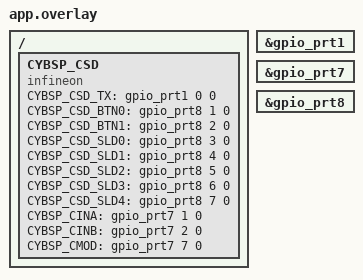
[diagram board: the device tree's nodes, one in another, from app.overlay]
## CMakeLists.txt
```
# SPDX-License-Identifier: Apache-2.0

cmake_minimum_required(VERSION 3.20.0)

find_package(Zephyr REQUIRED HINTS $ENV{ZEPHYR_BASE})
project(capsense_buttons_slider)

set(PDL_DRIVER_DIR ${ZEPHYR_HAL_INFINEON_MODULE_DIR}/mtb-pdl-cat1/drivers/source)
set(HAL_SOURCE_DIR ${ZEPHYR_HAL_INFINEON_MODULE_DIR}/mtb-hal-cat1/COMPONENT_PSOC6HAL/source)
set(CAPSENSE_LIB_DIR "${ZEPHYR_HAL_INFINEON_MODULE_DIR}/../../lib/capsense")

zephyr_library_sources(${PDL_DRIVER_DIR}/cy_tcpwm_pwm.c ${PDL_DRIVER_DIR}/cy_scb_ezi2c.c ${PDL_DRIVER_DIR}/cy_scb_i2c.c)
zephyr_library_sources(${HAL_SOURCE_DIR}/cyhal_pwm.c ${HAL_SOURCE_DIR}/cyhal_tcpwm_common.c ${HAL_SOURCE_DIR}/cyhal_ezi2c.c)
zephyr_include_directories(${CAPSENSE_LIB_DIR})
FILE(GLOB capsense_sources ${CAPSENSE_LIB_DIR}/*.c)
zephyr_library_sources(${capsense_sources} ${PDL_DRIVER_DIR}/cy_csd.c)

add_definitions( -DCOMPONENT_CUSTOM_DESIGN_MODUS )

zephyr_include_directories(GeneratedSource src)
FILE(GLOB app_sources GeneratedSource/*c src/*.c)
target_sources(app PRIVATE ${app_sources})

add_library(libcy_capsense STATIC IMPORTED GLOBAL)
set_target_properties(libcy_capsense PROPERTIES IMPORTED_LOCATION ${CAPSENSE_LIB_DIR}/COMPONENT_SOFTFP/TOOLCHAIN_GCC_ARM/libcy_capsense.a)
target_link_libraries(app PUBLIC libcy_capsense)
```

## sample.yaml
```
sample:
  name: CAPSENSE Buttons and Slider
tests:
  sample.basic.capsense:
    tags: gpio
    filter: dt_enabled_alias_with_parent_compat("gpio-led")
    depends_on: gpio
    harness: gpio
```

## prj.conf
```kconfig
CONFIG_NEWLIB_LIBC=y
CONFIG_BOOT_BANNER=n
```

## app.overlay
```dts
/*
 * Copyright (c) 2021 Nordic Semiconductor ASA
 *
 * SPDX-License-Identifier: Apache-2.0
 */

/ {
	/* CAPSENSE configuration */
	CYBSP_CSD {
	status = "okay";
	compatible = "infineon";

	/* CAPSENSE pins */
	CYBSP_CSD_TX   = <&gpio_prt1 0 0>;
	CYBSP_CSD_BTN0 = <&gpio_prt8 1 0>;
	CYBSP_CSD_BTN1 = <&gpio_prt8 2 0>;
	CYBSP_CSD_SLD0 = <&gpio_prt8 3 0>;
	CYBSP_CSD_SLD1 = <&gpio_prt8 4 0>;
	CYBSP_CSD_SLD2 = <&gpio_prt8 5 0>;
	CYBSP_CSD_SLD3 = <&gpio_prt8 6 0>;
	CYBSP_CSD_SLD4 = <&gpio_prt8 7 0>;
	CYBSP_CINA     = <&gpio_prt7 1 0>;
	CYBSP_CINB     = <&gpio_prt7 2 0>;
	CYBSP_CMOD     = <&gpio_prt7 7 0>;
	};
};

&gpio_prt1 {
	status = "okay";
};

&gpio_prt7 {
	status = "okay";
};

&gpio_prt8 {
	status = "okay";
};
```

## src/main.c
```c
/******************************************************************************
* File Name: main.c
*
* Description: This code example features a 5-segment CAPSENSE slider and two
*              CAPSENSE buttons. Button 0 turns the LED ON, Button 1 turns the
*              LED OFF, and the slider controls the brightness of the LED. The
*              code example also features interfacing with Tuner GUI using I2C
*              interface.
*
*              This code example uses Zephyr. For documentation and API
*              references of Zephyr, visit : https://docs.zephyrproject.org
*
* Related Document: See README.md
*
*
*******************************************************************************
* Copyright 2019-2023, Cypress Semiconductor Corporation (an Infineon company) or
* an affiliate of Cypress Semiconductor Corporation.  All rights reserved.
*
* This software, including source code, documentation and related
* materials ("Software") is owned by Cypress Semiconductor Corporation
* or one of its affiliates ("Cypress") and is protected by and subject to
* worldwide patent protection (United States and foreign),
* United States copyright laws and international treaty provisions.
* Therefore, you may use this Software only as provided in the license
* agreement accompanying the software package from which you
* obtained this Software ("EULA").
* If no EULA applies, Cypress hereby grants you a personal, non-exclusive,
* non-transferable license to copy, modify, and compile the Software
* source code solely for use in connection with Cypress's
* integrated circuit products.  Any reproduction, modification, translation,
* compilation, or representation of this Software except as specified
* above is prohibited without the express written permission of Cypress.
*
* Disclaimer: THIS SOFTWARE IS PROVIDED AS-IS, WITH NO WARRANTY OF ANY KIND,
* EXPRESS OR IMPLIED, INCLUDING, BUT NOT LIMITED TO, NONINFRINGEMENT, IMPLIED
* WARRANTIES OF MERCHANTABILITY AND FITNESS FOR A PARTICULAR PURPOSE. Cypress
* reserves the right to make changes to the Software without notice. Cypress
* does not assume any liability arising out of the application or use of the
* Software or any product or circuit described in the Software. Cypress does
* not authorize its products for use in any products where a malfunction or
* failure of the Cypress product may reasonably be expected to result in
* significant property damage, injury or death ("High Risk Product"). By
* including Cypress's product in a High Risk Product, the manufacturer
* of such system or application assumes all risk of such use and in doing
* so agrees to indemnify Cypress against all liability.
*******************************************************************************/

#include "cybsp.h"
#include "capsense_task.h"
#include "led_task.h"
#include <zephyr/device.h>


/*******************************************************************************
 * Global constants
 ******************************************************************************/
/* Priorities of user tasks in this project. */
#define TASK_CAPSENSE_PRIORITY   (6u)
#define TASK_LED_PRIORITY        (5u)

/* Stack sizes of user tasks in this project */
#define TASK_CAPSENSE_STACK_SIZE (1024u)
#define TASK_LED_STACK_SIZE      (512u)


/*******************************************************************************
 * Global variable
 ******************************************************************************/
/* Create the threads. See the respective task definition for more
    * details of these tasks.
    */
K_THREAD_DEFINE(task_capsense_id, TASK_CAPSENSE_STACK_SIZE, task_capsense,
            NULL, NULL, NULL, TASK_CAPSENSE_PRIORITY, 0, -1);
K_THREAD_DEFINE(task_led_id, TASK_LED_STACK_SIZE, task_led,
            NULL, NULL, NULL, TASK_LED_PRIORITY, 0, -1);


/*******************************************************************************
* Function Name: main()
********************************************************************************
* Summary:
*  System entrance point. This function sets up user tasks and then starts
*  the RTOS scheduler.
*
* Return:
*  int
*
*******************************************************************************/
void main(void)
{
    cy_rslt_t result;

    /* Initialize the device and board peripherals */
    result = cybsp_init();

    /* Board init failed. Stop program execution */
    if (result != CY_RSLT_SUCCESS)
    {
        CY_ASSERT(0);
    }

    /* Enable global interrupts */
    __enable_irq();

    /* Started the created threads */
    k_thread_start(task_capsense_id);
    k_thread_start(task_led_id);
}


/* [] END OF FILE */
```

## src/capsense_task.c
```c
/*******************************************************************************
* File Name: capsense_task.c
*
* Description: This file contains the task that handles touch sensing.
*
* Related Document: README.md
*
*******************************************************************************
* Copyright 2019-2023, Cypress Semiconductor Corporation (an Infineon company) or
* an affiliate of Cypress Semiconductor Corporation.  All rights reserved.
*
* This software, including source code, documentation and related
* materials ("Software") is owned by Cypress Semiconductor Corporation
* or one of its affiliates ("Cypress") and is protected by and subject to
* worldwide patent protection (United States and foreign),
* United States copyright laws and international treaty provisions.
* Therefore, you may use this Software only as provided in the license
* agreement accompanying the software package from which you
* obtained this Software ("EULA").
* If no EULA applies, Cypress hereby grants you a personal, non-exclusive,
* non-transferable license to copy, modify, and compile the Software
* source code solely for use in connection with Cypress's
* integrated circuit products.  Any reproduction, modification, translation,
* compilation, or representation of this Software except as specified
* above is prohibited without the express written permission of Cypress.
*
* Disclaimer: THIS SOFTWARE IS PROVIDED AS-IS, WITH NO WARRANTY OF ANY KIND,
* EXPRESS OR IMPLIED, INCLUDING, BUT NOT LIMITED TO, NONINFRINGEMENT, IMPLIED
* WARRANTIES OF MERCHANTABILITY AND FITNESS FOR A PARTICULAR PURPOSE. Cypress
* reserves the right to make changes to the Software without notice. Cypress
* does not assume any liability arising out of the application or use of the
* Software or any product or circuit described in the Software. Cypress does
* not authorize its products for use in any products where a malfunction or
* failure of the Cypress product may reasonably be expected to result in
* significant property damage, injury or death ("High Risk Product"). By
* including Cypress's product in a High Risk Product, the manufacturer
* of such system or application assumes all risk of such use and in doing
* so agrees to indemnify Cypress against all liability.
*******************************************************************************/


/******************************************************************************
* Header files includes
******************************************************************************/
#include "cybsp.h"
#include "cycfg.h"
#include "cyhal.h"
#include "cycfg_capsense.h"
#include "capsense_task.h"
#include "led_task.h"


/*******************************************************************************
* Global constants
*******************************************************************************/
#define CAPSENSE_INTERRUPT_PRIORITY    (7u)
#define EZI2C_INTERRUPT_PRIORITY    (6u)    /* EZI2C interrupt priority must be
                                             * higher than CAPSENSE interrupt
                                             */
#define CAPSENSE_SCAN_INTERVAL_MS    (20u)   /* in milliseconds*/


/*******************************************************************************
* Function Prototypes
*******************************************************************************/
static uint32_t capsense_init(void);
static void tuner_init(void);
static void process_touch(void);
static void capsense_isr(void);
static void capsense_end_of_scan_callback(cy_stc_active_scan_sns_t* active_scan_sns_ptr);
static void capsense_timer_callback(struct k_timer *params);
void handle_error(void);


/******************************************************************************
* Global variables
******************************************************************************/
cy_stc_scb_ezi2c_context_t ezi2c_context;
cyhal_ezi2c_t sEzI2C;
cyhal_ezi2c_slave_cfg_t sEzI2C_sub_cfg;
cyhal_ezi2c_cfg_t sEzI2C_cfg;

/* Queue handle used for LED data */
K_FIFO_DEFINE(capsense_command_q);
/* Initialize timer for periodic CAPSENSE scan */
K_TIMER_DEFINE(scan_timer_handle, capsense_timer_callback, NULL);

/* SysPm callback params */
cy_stc_syspm_callback_params_t callback_params =
{
    .base       = CYBSP_CSD_HW,
    .context    = &cy_capsense_context
};

cy_stc_syspm_callback_t capsense_deep_sleep_cb =
{
    Cy_CapSense_DeepSleepCallback,
    CY_SYSPM_DEEPSLEEP,
    (CY_SYSPM_SKIP_CHECK_FAIL | CY_SYSPM_SKIP_BEFORE_TRANSITION | CY_SYSPM_SKIP_AFTER_TRANSITION),
    &callback_params,
    NULL,
    NULL
};


/*******************************************************************************
* Function Name: handle_error
********************************************************************************
* Summary:
* User defined error handling function
*
* Parameters:
*  void
*
* Return:
*  void
*
*******************************************************************************/
void handle_error(void)
{
    /* Disable all interrupts. */
    __disable_irq();

    CY_ASSERT(0);
}


/*******************************************************************************
* Function Name: task_capsense
********************************************************************************
* Summary:
*  Task that initializes the CAPSENSE block and processes the touch input.
*
* Parameters:
*  void *param : Task parameter defined during task creation (unused)
*
*******************************************************************************/
void task_capsense(void *dummy1, void *dummy2, void *dummy3)
{
    cy_status status;
    capsense_command_t *capsense_cmd;

    /* Remove warning for unused parameter */
    ARG_UNUSED(dummy1);
	ARG_UNUSED(dummy2);
	ARG_UNUSED(dummy3);

    /* Setup communication between Tuner GUI and PSoC 6 MCU */
    tuner_init();

    /* Initialize CAPSENSE block */
    status = capsense_init();
    if(CY_RET_SUCCESS != status)
    {
        CY_ASSERT(0u);
    }

    /* Start the timer */
    k_timer_start(&scan_timer_handle, K_NO_WAIT,
                    K_MSEC(CAPSENSE_SCAN_INTERVAL_MS));

    /* Repeatedly running part of the task */
    for(;;)
    {
        /* Block until a CAPSENSE command has been received over queue */
        capsense_cmd = k_fifo_get(&capsense_command_q, K_FOREVER);

        /* Command has been received from capsense_cmd */
        /* Check if CAPSENSE is busy with a previous scan */
        if(CY_CAPSENSE_NOT_BUSY == Cy_CapSense_IsBusy(&cy_capsense_context))
        {
            switch(*capsense_cmd)
            {
                case CAPSENSE_SCAN:
                {
                    /* Start scan */
                    Cy_CapSense_ScanAllWidgets(&cy_capsense_context);
                    break;
                }
                case CAPSENSE_PROCESS:
                {
                    /* Process all widgets */
                    Cy_CapSense_ProcessAllWidgets(&cy_capsense_context);
                    process_touch();

                    /* Establishes synchronized operation between the CAPSENSE
                        * middleware and the CAPSENSE Tuner tool.
                        */
                    Cy_CapSense_RunTuner(&cy_capsense_context);
                    break;
                }
                /* Invalid command */
                default:
                {
                    break;
                }
            }
        }
    }
}


/*******************************************************************************
* Function Name: process_touch
********************************************************************************
* Summary:
*  This function processes the touch input and sends command to LED task.
*
*******************************************************************************/
static void process_touch(void)
{
    /* Variables used to store touch information */
    uint32_t button0_status = 0;
    uint32_t button1_status = 0;
    uint16_t slider_pos = 0;
    uint8_t slider_touched = 0;
    cy_stc_capsense_touch_t *slider_touch;

    /* Variables used to store previous touch information */
    static uint32_t button0_status_prev = 0;
    static uint32_t button1_status_prev = 0;
    static uint16_t slider_pos_perv = 0;

    /* Variables used for storing command and data for LED Task */
    led_command_data_t led_cmd_data;
    bool send_led_command = false;

    /* Get button 0 status */
    button0_status = Cy_CapSense_IsSensorActive(
        CY_CAPSENSE_BUTTON0_WDGT_ID,
        CY_CAPSENSE_BUTTON0_SNS0_ID,
        &cy_capsense_context);

    /* Get button 1 status */
    button1_status = Cy_CapSense_IsSensorActive(
        CY_CAPSENSE_BUTTON1_WDGT_ID,
        CY_CAPSENSE_BUTTON1_SNS0_ID,
        &cy_capsense_context);

    /* Get slider status */
    slider_touch = Cy_CapSense_GetTouchInfo(
        CY_CAPSENSE_LINEARSLIDER0_WDGT_ID,
        &cy_capsense_context);
    slider_pos = slider_touch->ptrPosition->x;
    slider_touched = slider_touch->numPosition;

    /* Detect new touch on Button0 */
    if((0u != button0_status) && (0u == button0_status_prev))
    {
        led_cmd_data.command = LED_TURN_ON;
        send_led_command = true;
    }

    /* Detect new touch on Button1 */
    if((0u != button1_status) && (0u == button1_status_prev))
    {
        led_cmd_data.command = LED_TURN_OFF;
        send_led_command = true;
    }

    /* Detect new touch on slider */
    if((0u != slider_touched) && (slider_pos_perv != slider_pos ))
    {
        led_cmd_data.command = LED_UPDATE_BRIGHTNESS;

        /* brightness in percentage */
        led_cmd_data.brightness = (slider_pos * 100)
                    / cy_capsense_context.ptrWdConfig[CY_CAPSENSE_LINEARSLIDER0_WDGT_ID].xResolution;
        send_led_command = true;
    }

    /* Send command to update LED state if required */
    if(send_led_command)
    {
        k_fifo_put(&led_command_data_q, &led_cmd_data);
    }

    /* Update previous touch status */
    button0_status_prev = button0_status;
    button1_status_prev = button1_status;
    slider_pos_perv = slider_pos;
}


/*******************************************************************************
* Function Name: capsense_init
********************************************************************************
* Summary:
*  This function initializes the CSD HW block, and configures the CAPSENSE
*  interrupt.
*
*******************************************************************************/
static uint32_t capsense_init(void)
{
    uint32_t status = CYRET_SUCCESS;

    /* CAPSENSE interrupt configuration parameters */
    static const cy_stc_sysint_t capSense_intr_config =
    {
        .intrSrc = csd_interrupt_IRQn,
        .intrPriority = CAPSENSE_INTERRUPT_PRIORITY,
    };

    /*Initialize CAPSENSE Data structures */
    status = Cy_CapSense_Init(&cy_capsense_context);
    if (CYRET_SUCCESS != status)
    {
        return status;
    }

    /* Initialize CAPSENSE interrupt */
    cyhal_system_set_isr(csd_interrupt_IRQn, csd_interrupt_IRQn, CAPSENSE_INTERRUPT_PRIORITY, &capsense_isr);
    NVIC_ClearPendingIRQ(capSense_intr_config.intrSrc);
    NVIC_EnableIRQ(capSense_intr_config.intrSrc);

    /* Initialize the CAPSENSE deep sleep callback functions. */
    Cy_CapSense_Enable(&cy_capsense_context);
    if (CYRET_SUCCESS != status)
    {
        return status;
    }
    Cy_SysPm_RegisterCallback(&capsense_deep_sleep_cb);
    /* Register end of scan callback */
    status = Cy_CapSense_RegisterCallback(CY_CAPSENSE_END_OF_SCAN_E,
                                              capsense_end_of_scan_callback, &cy_capsense_context);
    if (CYRET_SUCCESS != status)
    {
        return status;
    }

    return status;
}


/*******************************************************************************
* Function Name: capsense_end_of_scan_callback
********************************************************************************
* Summary:
*  CAPSENSE end of scan callback function. This function sends a command to
*  CAPSENSE task to process scan.
*
* Parameters:
*  cy_stc_active_scan_sns_t * active_scan_sns_ptr (unused)
*
*******************************************************************************/
static void capsense_end_of_scan_callback(cy_stc_active_scan_sns_t* active_scan_sns_ptr)
{
    ARG_UNUSED(active_scan_sns_ptr);

    /* Send command to process CAPSENSE data */
    static capsense_command_t command = CAPSENSE_PROCESS;
    k_fifo_put(&capsense_command_q, &command);
}


/*******************************************************************************
* Function Name: capsense_timer_callback
********************************************************************************
* Summary:
*  CAPSENSE timer callback. This function sends a command to start CAPSENSE
*  scan.
*
* Parameters:
*  struct k_timer dummy (unused)
*
*******************************************************************************/
static void capsense_timer_callback(struct k_timer *dummy)
{
    Cy_CapSense_Wakeup(&cy_capsense_context);
    static capsense_command_t command = CAPSENSE_SCAN;

    ARG_UNUSED(dummy);

    /* Send command to start CAPSENSE scan */
    k_fifo_put(&capsense_command_q, &command);
}


/*******************************************************************************
* Function Name: capsense_isr
********************************************************************************
* Summary:
*  Wrapper function for handling interrupts from CSD block.
*
*******************************************************************************/
static void capsense_isr(void)
{
    Cy_CapSense_InterruptHandler(CYBSP_CSD_HW, &cy_capsense_context);
}


/*******************************************************************************
* Function Name: tuner_init
********************************************************************************
* Summary:
*  Initializes communication between Tuner GUI and PSoC 6 MCU.
*
*******************************************************************************/
static void tuner_init(void)
{
    cy_rslt_t result;
    /* Configure CAPSENSE Tuner as EzI2C Slave */
    sEzI2C_sub_cfg.buf = (uint8_t *)&cy_capsense_tuner;
    sEzI2C_sub_cfg.buf_rw_boundary = sizeof(cy_capsense_tuner);
    sEzI2C_sub_cfg.buf_size = sizeof(cy_capsense_tuner);
    sEzI2C_sub_cfg.slave_address = 8U;

    sEzI2C_cfg.data_rate = CYHAL_EZI2C_DATA_RATE_400KHZ;
    sEzI2C_cfg.enable_wake_from_sleep = true;
    sEzI2C_cfg.slave1_cfg = sEzI2C_sub_cfg;
    sEzI2C_cfg.sub_address_size = CYHAL_EZI2C_SUB_ADDR16_BITS;
    sEzI2C_cfg.two_addresses = false;
    result = cyhal_ezi2c_init( &sEzI2C, CYBSP_I2C_SDA, CYBSP_I2C_SCL, NULL, &sEzI2C_cfg);
    if (result != CY_RSLT_SUCCESS)
    {
        handle_error();
    }

}


/* END OF FILE [] */
```

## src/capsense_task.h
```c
/******************************************************************************
* File Name: capsense_task.h
*
* Description: This file is the public interface of capsense_task.c source
*              file.
*
* Related Document: README.md
*
*******************************************************************************
* Copyright 2019-2023, Cypress Semiconductor Corporation (an Infineon company) or
* an affiliate of Cypress Semiconductor Corporation.  All rights reserved.
*
* This software, including source code, documentation and related
* materials ("Software") is owned by Cypress Semiconductor Corporation
* or one of its affiliates ("Cypress") and is protected by and subject to
* worldwide patent protection (United States and foreign),
* United States copyright laws and international treaty provisions.
* Therefore, you may use this Software only as provided in the license
* agreement accompanying the software package from which you
* obtained this Software ("EULA").
* If no EULA applies, Cypress hereby grants you a personal, non-exclusive,
* non-transferable license to copy, modify, and compile the Software
* source code solely for use in connection with Cypress's
* integrated circuit products.  Any reproduction, modification, translation,
* compilation, or representation of this Software except as specified
* above is prohibited without the express written permission of Cypress.
*
* Disclaimer: THIS SOFTWARE IS PROVIDED AS-IS, WITH NO WARRANTY OF ANY KIND,
* EXPRESS OR IMPLIED, INCLUDING, BUT NOT LIMITED TO, NONINFRINGEMENT, IMPLIED
* WARRANTIES OF MERCHANTABILITY AND FITNESS FOR A PARTICULAR PURPOSE. Cypress
* reserves the right to make changes to the Software without notice. Cypress
* does not assume any liability arising out of the application or use of the
* Software or any product or circuit described in the Software. Cypress does
* not authorize its products for use in any products where a malfunction or
* failure of the Cypress product may reasonably be expected to result in
* significant property damage, injury or death ("High Risk Product"). By
* including Cypress's product in a High Risk Product, the manufacturer
* of such system or application assumes all risk of such use and in doing
* so agrees to indemnify Cypress against all liability.
*******************************************************************************/


/*******************************************************************************
 *  Include guard
 ******************************************************************************/
#ifndef SOURCE_CAPSENSE_TASK_H_
#define SOURCE_CAPSENSE_TASK_H_


/*******************************************************************************
 * Header file includes
 ******************************************************************************/
#include <zephyr/kernel.h>


/*******************************************************************************
 * Enumeration
 ******************************************************************************/
typedef enum
{
    CAPSENSE_SCAN,
    CAPSENSE_PROCESS
} capsense_command_t;


/*******************************************************************************
 * Global variable
 ******************************************************************************/


/*******************************************************************************
 * Function prototype
 ******************************************************************************/
void task_capsense(void *dummy1, void *dummy2, void *dummy3);


#endif /* SOURCE_CAPSENSE_TASK_H_ */


/* END OF FILE [] */
```

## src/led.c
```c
/******************************************************************************
* File Name: led.c
*
* Description: This file contains source code that controls LED.
*
* Related Document: README.md
*
*******************************************************************************
* Copyright 2019-2023, Cypress Semiconductor Corporation (an Infineon company) or
* an affiliate of Cypress Semiconductor Corporation.  All rights reserved.
*
* This software, including source code, documentation and related
* materials ("Software") is owned by Cypress Semiconductor Corporation
* or one of its affiliates ("Cypress") and is protected by and subject to
* worldwide patent protection (United States and foreign),
* United States copyright laws and international treaty provisions.
* Therefore, you may use this Software only as provided in the license
* agreement accompanying the software package from which you
* obtained this Software ("EULA").
* If no EULA applies, Cypress hereby grants you a personal, non-exclusive,
* non-transferable license to copy, modify, and compile the Software
* source code solely for use in connection with Cypress's
* integrated circuit products.  Any reproduction, modification, translation,
* compilation, or representation of this Software except as specified
* above is prohibited without the express written permission of Cypress.
*
* Disclaimer: THIS SOFTWARE IS PROVIDED AS-IS, WITH NO WARRANTY OF ANY KIND,
* EXPRESS OR IMPLIED, INCLUDING, BUT NOT LIMITED TO, NONINFRINGEMENT, IMPLIED
* WARRANTIES OF MERCHANTABILITY AND FITNESS FOR A PARTICULAR PURPOSE. Cypress
* reserves the right to make changes to the Software without notice. Cypress
* does not assume any liability arising out of the application or use of the
* Software or any product or circuit described in the Software. Cypress does
* not authorize its products for use in any products where a malfunction or
* failure of the Cypress product may reasonably be expected to result in
* significant property damage, injury or death ("High Risk Product"). By
* including Cypress's product in a High Risk Product, the manufacturer
* of such system or application assumes all risk of such use and in doing
* so agrees to indemnify Cypress against all liability.
*******************************************************************************/

/*******************************************************************************
* Header files includes
*******************************************************************************/
#include "cybsp.h"
#include "cyhal.h"
#include "cycfg.h"
#include "led.h"

/*******************************************************************************
* Global constants
*******************************************************************************/
#define PWM_LED_FREQ_HZ    (1000000lu)  /* in Hz */
#define GET_DUTY_CYCLE(x)    (100 - x)

/*******************************************************************************
* Global constants
*******************************************************************************/
led_state_t led_state_cur = LED_OFF;
cyhal_pwm_t pwm_led;

/*******************************************************************************
* Function Name: update_led_state
********************************************************************************
* Summary:
*  This function updates the LED state, based on the touch input.
*
* Parameter:
*  ledData: the pointer to the LED data structure
*
*******************************************************************************/
void update_led_state(led_data_t *ledData)
{
    if ((led_state_cur == LED_OFF) && (ledData->state == LED_ON))
    {
        cyhal_pwm_start(&pwm_led);
        led_state_cur = LED_ON;
        ledData->brightness = LED_MAX_BRIGHTNESS;
    }
    else if ((led_state_cur == LED_ON) && (ledData->state == LED_OFF))
    {
        cyhal_pwm_stop(&pwm_led);
        led_state_cur = LED_OFF;
        ledData->brightness = 0;
    }
    else
    {
    }

    if ((LED_ON == led_state_cur) || ((LED_OFF == led_state_cur) && (ledData->brightness > 0)))
    {
        cyhal_pwm_start(&pwm_led);
        uint32_t brightness = (ledData->brightness < LED_MIN_BRIGHTNESS) ? LED_MIN_BRIGHTNESS : ledData->brightness;

        /* Drive the LED with brightness */
        cyhal_pwm_set_duty_cycle(&pwm_led, GET_DUTY_CYCLE(brightness),
                                 PWM_LED_FREQ_HZ);
        led_state_cur = LED_ON;
    }
}

/*******************************************************************************
* Function Name: initialize_led
********************************************************************************
* Summary:
*  Initializes a PWM resource for driving an LED.
*
*******************************************************************************/
cy_rslt_t initialize_led(void)
{
    cy_rslt_t rslt;

    rslt = cyhal_pwm_init(&pwm_led, CYBSP_USER_LED, NULL);

    if (CY_RSLT_SUCCESS == rslt)
    {
        rslt = cyhal_pwm_set_duty_cycle(&pwm_led,
                                        GET_DUTY_CYCLE(LED_MAX_BRIGHTNESS),
                                        PWM_LED_FREQ_HZ);
        if (CY_RSLT_SUCCESS == rslt)
        {
            rslt = cyhal_pwm_start(&pwm_led);
        }

    }

    if (CY_RSLT_SUCCESS == rslt)
    {
        led_state_cur = LED_ON;
    }

    return rslt;
}

/* [] END OF FILE */
```

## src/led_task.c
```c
/******************************************************************************
* File Name: led_task.c
*
* Description: This file contains the task that handles led.
*
* Related Document: README.md
*
*******************************************************************************
* Copyright 2019-2023, Cypress Semiconductor Corporation (an Infineon company) or
* an affiliate of Cypress Semiconductor Corporation.  All rights reserved.
*
* This software, including source code, documentation and related
* materials ("Software") is owned by Cypress Semiconductor Corporation
* or one of its affiliates ("Cypress") and is protected by and subject to
* worldwide patent protection (United States and foreign),
* United States copyright laws and international treaty provisions.
* Therefore, you may use this Software only as provided in the license
* agreement accompanying the software package from which you
* obtained this Software ("EULA").
* If no EULA applies, Cypress hereby grants you a personal, non-exclusive,
* non-transferable license to copy, modify, and compile the Software
* source code solely for use in connection with Cypress's
* integrated circuit products.  Any reproduction, modification, translation,
* compilation, or representation of this Software except as specified
* above is prohibited without the express written permission of Cypress.
*
* Disclaimer: THIS SOFTWARE IS PROVIDED AS-IS, WITH NO WARRANTY OF ANY KIND,
* EXPRESS OR IMPLIED, INCLUDING, BUT NOT LIMITED TO, NONINFRINGEMENT, IMPLIED
* WARRANTIES OF MERCHANTABILITY AND FITNESS FOR A PARTICULAR PURPOSE. Cypress
* reserves the right to make changes to the Software without notice. Cypress
* does not assume any liability arising out of the application or use of the
* Software or any product or circuit described in the Software. Cypress does
* not authorize its products for use in any products where a malfunction or
* failure of the Cypress product may reasonably be expected to result in
* significant property damage, injury or death ("High Risk Product"). By
* including Cypress's product in a High Risk Product, the manufacturer
* of such system or application assumes all risk of such use and in doing
* so agrees to indemnify Cypress against all liability.
*******************************************************************************/


/*******************************************************************************
 * Header file includes
 ******************************************************************************/
#include "cybsp.h"
#include "cycfg.h"
#include "cyhal.h"
#include "led_task.h"


/*******************************************************************************
* Global constants
*******************************************************************************/
#define PWM_LED_FREQ_HZ     (1000000u)  /* in Hz */
#define GET_DUTY_CYCLE(x)   (100 - x)   /* subtracting from 100 since the LED
                                         * is connected in active low
                                         * configuration
                                         */


/*******************************************************************************
 * Global variable
 ******************************************************************************/
/* Queue handle used for LED data */
K_FIFO_DEFINE(led_command_data_q);


/*******************************************************************************
* Function Name: task_led
********************************************************************************
* Summary:
*  Task that controls the LED.
*
* Parameters:
*  void *param : Task parameter defined during task creation (unused)
*
*******************************************************************************/
void task_led(void *dummy1, void *dummy2, void *dummy3)
{
    cyhal_pwm_t pwm_led;
    bool led_on = true;
    led_command_data_t *led_cmd_data;

    /* Suppress warning for unused parameter */
    ARG_UNUSED(dummy1);
	ARG_UNUSED(dummy2);
	ARG_UNUSED(dummy3);

    /* Initialize a PWM resource for driving an LED. */
    cyhal_pwm_init(&pwm_led, CYBSP_USER_LED, NULL);
    cyhal_pwm_set_duty_cycle(&pwm_led, GET_DUTY_CYCLE(LED_MAX_BRIGHTNESS),
                             PWM_LED_FREQ_HZ);
    cyhal_pwm_start(&pwm_led);

    /* Repeatedly running part of the task */
    for(;;)
    {
        /* Block until a command has been received over queue */
        led_cmd_data = k_fifo_get(&led_command_data_q, K_FOREVER);

        /* Command has been received from queue */
        switch(led_cmd_data->command)
        {
            /* Turn on the LED. */
            case LED_TURN_ON:
            {
                if (!led_on)
                {
                    /* Start PWM to turn the LED on */
                    cyhal_pwm_start(&pwm_led);
                    led_on = true;
                    led_cmd_data->brightness=LED_MAX_BRIGHTNESS;
                }
                break;
            }
            /* Turn off LED */
            case LED_TURN_OFF:
            {
                if(led_on)
                {
                    /* Stop PWM to turn the LED off */
                    cyhal_pwm_stop(&pwm_led);
                    led_on = false;
                    led_cmd_data->brightness=0;
                }
                break;
            }
            /* Update LED brightness */
            case LED_UPDATE_BRIGHTNESS:
            {
                if ((led_on) || ((!led_on) && (led_cmd_data->brightness>0)))
                {
                    /* Start PWM to turn the LED on */
                    cyhal_pwm_start(&pwm_led);
                    uint32_t brightness = (led_cmd_data->brightness < LED_MIN_BRIGHTNESS) ?
                                            LED_MIN_BRIGHTNESS : led_cmd_data->brightness;

                    /* Drive the LED with brightness */
                    cyhal_pwm_set_duty_cycle(&pwm_led, GET_DUTY_CYCLE(brightness),
                                                PWM_LED_FREQ_HZ);
                    led_on = true;
                }
                break;
            }
            /* Invalid command */
            default:
            {
                /* Handle invalid command here */
                break;
            }
        }
    }
}


/* END OF FILE [] */
```

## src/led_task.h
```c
/******************************************************************************
* File Name: led_task.h
*
* Description: This file is the public interface of led_task.c source file
*
* Related Document: README.md
*
*******************************************************************************
* Copyright 2019-2023, Cypress Semiconductor Corporation (an Infineon company) or
* an affiliate of Cypress Semiconductor Corporation.  All rights reserved.
*
* This software, including source code, documentation and related
* materials ("Software") is owned by Cypress Semiconductor Corporation
* or one of its affiliates ("Cypress") and is protected by and subject to
* worldwide patent protection (United States and foreign),
* United States copyright laws and international treaty provisions.
* Therefore, you may use this Software only as provided in the license
* agreement accompanying the software package from which you
* obtained this Software ("EULA").
* If no EULA applies, Cypress hereby grants you a personal, non-exclusive,
* non-transferable license to copy, modify, and compile the Software
* source code solely for use in connection with Cypress's
* integrated circuit products.  Any reproduction, modification, translation,
* compilation, or representation of this Software except as specified
* above is prohibited without the express written permission of Cypress.
*
* Disclaimer: THIS SOFTWARE IS PROVIDED AS-IS, WITH NO WARRANTY OF ANY KIND,
* EXPRESS OR IMPLIED, INCLUDING, BUT NOT LIMITED TO, NONINFRINGEMENT, IMPLIED
* WARRANTIES OF MERCHANTABILITY AND FITNESS FOR A PARTICULAR PURPOSE. Cypress
* reserves the right to make changes to the Software without notice. Cypress
* does not assume any liability arising out of the application or use of the
* Software or any product or circuit described in the Software. Cypress does
* not authorize its products for use in any products where a malfunction or
* failure of the Cypress product may reasonably be expected to result in
* significant property damage, injury or death ("High Risk Product"). By
* including Cypress's product in a High Risk Product, the manufacturer
* of such system or application assumes all risk of such use and in doing
* so agrees to indemnify Cypress against all liability.
*******************************************************************************/


/*******************************************************************************
 * Include guard
 ******************************************************************************/
#ifndef SOURCE_LED_TASK_H_
#define SOURCE_LED_TASK_H_


/*******************************************************************************
 * Header file includes
 ******************************************************************************/
#include <zephyr/kernel.h>


/*******************************************************************************
* Global constants
*******************************************************************************/
/* Allowed TCPWM compare value for maximum brightness */
#define LED_MAX_BRIGHTNESS  (100u)

/* Allowed TCPWM compare value for minimum brightness*/
#define LED_MIN_BRIGHTNESS  (2u)


/*******************************************************************************
 * Data structure and enumeration
 ******************************************************************************/
/* Available LED commands */
typedef enum
{
    LED_TURN_ON,
    LED_TURN_OFF,
    LED_UPDATE_BRIGHTNESS,
} led_command_t;

/* Structure used for storing LED data */
typedef struct
{
    led_command_t command;
    uint32_t brightness;
} led_command_data_t;


/*******************************************************************************
 * Global variable
 ******************************************************************************/
extern struct k_fifo led_command_data_q;


/*******************************************************************************
 * Function prototype
 ******************************************************************************/
void task_led(void *dummy1, void *dummy2, void *dummy3);


#endif /* SOURCE_LED_TASK_H_ */


/* [] END OF FILE */
```
